# ble_rfcore_rdbell_cm0p_secure register map
Vendor: Texas Instruments
Peripheral module from a debugger description file (folder CC35X1E).
Registers are 32-bit, access per field, reset 0x0 unless marked. A register's access mark holds for its fields unless they carry their own. Offsets are as the file gives them; lines under a group give offsets from that group; [hi:lo] are bit positions; {n}, {i} and the like mark numbered series; 'fields as' and 'values as' point back to an identical list; <NAME> marks a mode.

## ble_rfcore_rdbell_cm0p_secure
0x100 cpecmdr ro — CPE Command Register
  [31:0] CMD — Command register read.
0x104 cpecmdsta rw — CPE Command Status Register
  [31:0] STATUS — Status of the last command used. Raises IRQ to System CPU upon write
0x108 cpeirq rw — CPE Interrupt Register
  [31:0] CPEIRQ — Raise a software defined interrupt to System CPU
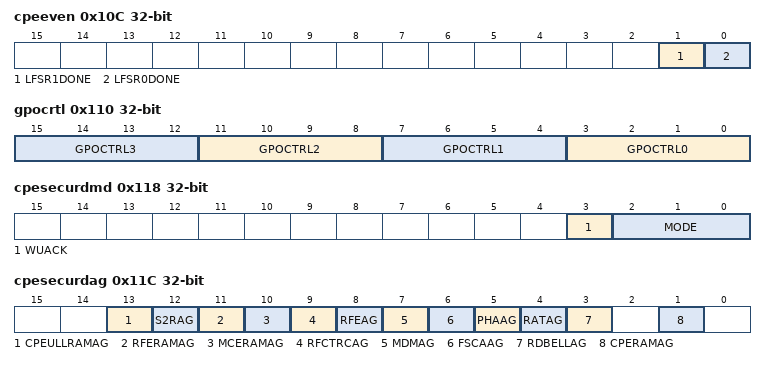
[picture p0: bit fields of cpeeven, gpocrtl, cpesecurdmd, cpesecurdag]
0x10C cpeeven — Enable event sources that should cause CPU input event for the CPE
  [1] LFSR1DONE rw — PHA LFSR1 done event enable
  [0] LFSR0DONE rw — PHA LFSR0 done event enable
0x110 gpocrtl — RF Core General Purpose Output Control
  [all] fields
    {v}=CPEGPO{v} (CPE GPO line {v}) (v=0..3); {v}=RFEGPO{v-8} (RFE GPO line {v-8}) (v=8..11); {v}=RATGPO{v-12} (RAT GPO line {v-12}) (v=12..15); {v}=MCEGPO{v-4} (MCE GPO line {v-4}) (v=4..7)
  [4n+3:4n] GPOCTRL{n} rw (n=0..3) — RF Core GPO control bit {n}. Selects which signal to output on the RF Core GPO line {n}.
0x114 cpegpo — CPE General Purpose Output Value
  [3:0] CPEGPO rw — Value to output on GPO lines from CPE
0x118 cpesecurdmd ro — CPE Secure Mode Status
  [3] WUACK — Wake-up request ack from outside
  [2:0] MODE — The defined secure mode for CPE operation
0x11C cpesecurdag — CPE Security Access Grant For System Access. Only Writable Once.
  [13] CPEULLRAMAG rw — Access granted to CPEULLRAM
  [12] S2RAG rw — Access granted to S2R
  [11] RFERAMAG rw — Access granted to RFERAM
  [10] MCERAMAG rw — Access granted to MCERAM
  [9] RFCTRCAG rw — Access granted to RFCTRC
  [8] RFEAG rw — Access granted to RFE
  [7] MDMAG rw — Access granted to MDM
  [6] FSCAAG rw — Access granted to FSCA
  [5] PHAAG rw — Access granted to PHA
  [4] RATAG rw — Access granted to RAT
  [3] RDBELLAG rw — Access granted to RDBELL
  [1] CPERAMAG rw — Access granted to CPERAM
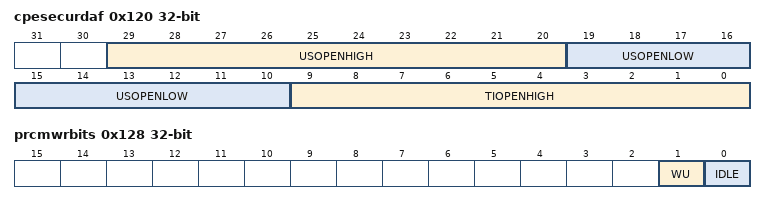
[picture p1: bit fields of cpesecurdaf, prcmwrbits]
0x120 cpesecurdaf — CPE Security Address Filter for CPE Access. Only Writable Once.
  [29:20] USOPENHIGH rw — User open high address for CPE ROM
  [19:10] USOPENLOW rw — User open low address for CPE ROM
  [9:0] TIOPENHIGH rw — TI open high address for CPE ROM (TI open low address is always addr 0)
0x124 prcmrdbits ro — PRCM Postbox Read Bits
  [31:0] RDBITS — Postbox data from PRCM
0x128 prcmwrbits — PRCM Postbox Write Bits
  [1] WU rw — System bus wake-up request towards PRCM
  [0] IDLE rw — CPE is Idling and can be switched off safely
0x12C fscairqflag — Frequency Synthesizer Interrupt Flag
  [0] FSCAIRQF rw — Set by frequency synthesizer, cleared by SW
0x130 rfcorestate
  [3:0] STATE rw — Indicates RF Core state information, to be set by CPE software
    0=NA (No Information yet avalaible or RF Core powered off); 1=IDLE (The RF Core is powered but idle. No RF.); 2=RFACTIVE (The RF Synthesizer is active); 6=RXWAIT (The RF Core is waiting for Sync); 10=TX (The RF Core is transmitting a packet); 14=RXPACKET (The RF Core is receiving a packet)
